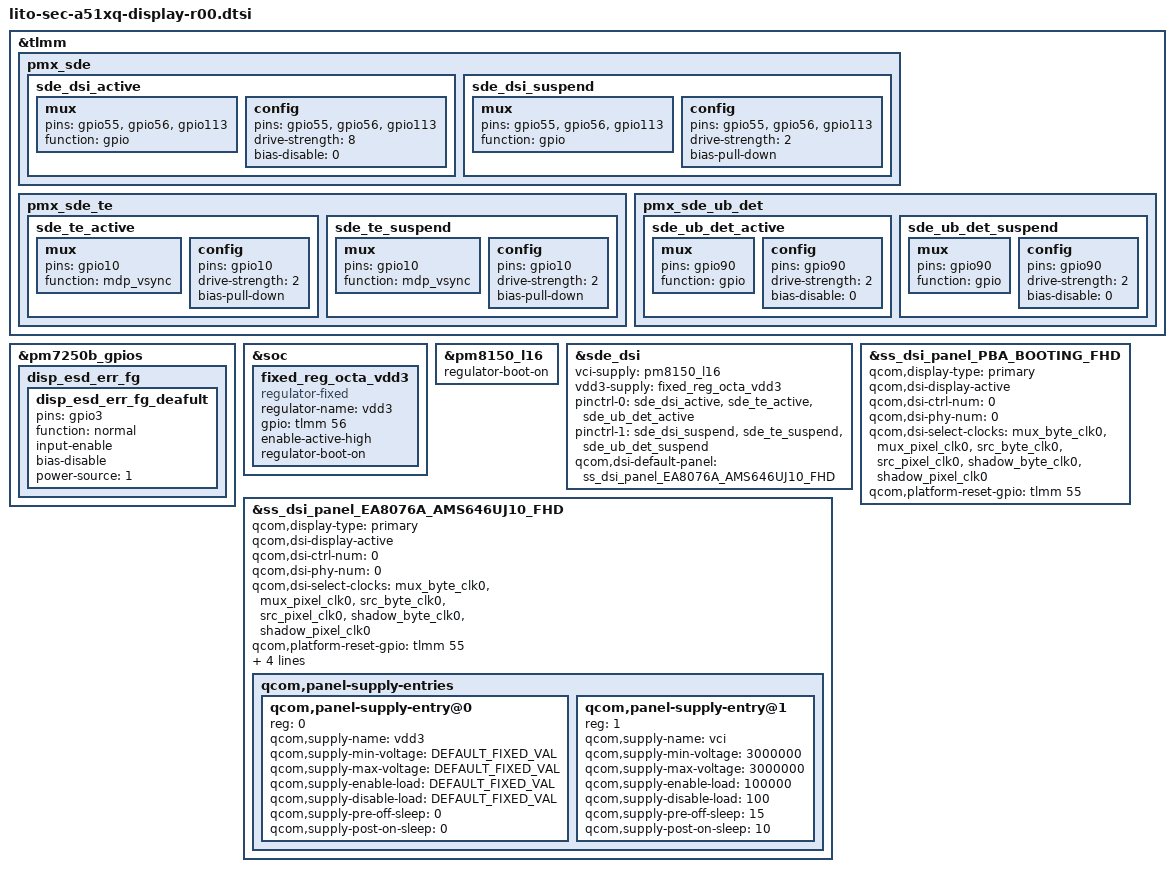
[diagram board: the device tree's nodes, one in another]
/* Copyright (c) 2016-2020, The Linux Foundation. All rights reserved.
 *
 * This program is free software; you can redistribute it and/or modify
 * it under the terms of the GNU General Public License version 2 and
 * only version 2 as published by the Free Software Foundation.
 *
 * This program is distributed in the hope that it will be useful,
 * but WITHOUT ANY WARRANTY; without even the implied warranty of
 * MERCHANTABILITY or FITNESS FOR A PARTICULAR PURPOSE.  See the
 * GNU General Public License for more details.
 */

#include "../../../../../../../techpack/display/msm/samsung/EA8076A_AMS646UJ10/dsi_panel_EA8076A_AMS646UJ10_fhd_octa_cmd.dtsi"
#include "../../../../../../../techpack/display/msm/samsung/PBA_BOOTING/dsi_panel_PBA_BOOTING_fhd_video.dtsi"

#define DEFAULT_FIXED_VAL	0

&tlmm {
	pmx_sde: pmx_sde {
		sde_dsi_active: sde_dsi_active {
			mux {
				pins = "gpio55", "gpio56", "gpio113";
				function = "gpio";
			};

			config {
				pins = "gpio55", "gpio56", "gpio113";
				drive-strength = <8>;   /* 8 mA */
				bias-disable = <0>;   /* no pull */
			};
		};
		sde_dsi_suspend: sde_dsi_suspend {
			mux {
				pins = "gpio55", "gpio56", "gpio113";
				function = "gpio";
			};

			config {
				pins = "gpio55", "gpio56", "gpio113";
				drive-strength = <2>;   /* 2 mA */
				bias-pull-down;         /* PULL DOWN */
			};
		};
	};

	pmx_sde_te {
		sde_te_active: sde_te_active {
			mux {
				pins = "gpio10";
				function = "mdp_vsync";
			};

			config {
				pins = "gpio10";
				drive-strength = <2>;   /* 2 mA */
				bias-pull-down;         /* PULL DOWN */
			};
		};

		sde_te_suspend: sde_te_suspend {
			mux {
				pins = "gpio10";
				function = "mdp_vsync";
			};

			config {
				pins = "gpio10";
				drive-strength = <2>;   /* 2 mA */
				bias-pull-down;         /* PULL DOWN */
			};
		};
	};

	pmx_sde_ub_det {
		sde_ub_det_active: sde_ub_det_active {	/* UB_CON_DET */
			mux {
				pins = "gpio90";
				function = "gpio";
			};

			config {
				pins = "gpio90";
				drive-strength = <2>;   /* 2 mA */
				bias-disable = <0>;   /* no pull */
			};
		};

		sde_ub_det_suspend: sde_ub_det_suspend {
			mux {
				pins = "gpio90";
				function = "gpio";
			};

			config {
				pins = "gpio90";
				drive-strength = <2>;   /* 2 mA */
				bias-disable = <0>;   /* no pull */
			};
		};
	};
};

&pm7250b_gpios {
	disp_esd_err_fg {
		disp_esd_err_fg_deafult: disp_esd_err_fg_deafult { // FG_ERR
			pins = "gpio3";
			function = "normal";
			input-enable;
			bias-disable;
			power-source = <1>;
		};
	};
};

&soc {
	fixed_reg_octa_vdd3: fixed_reg_octa_vdd3 {
		compatible = "regulator-fixed";
		status = "okay";
		regulator-name = "vdd3";
		gpio = <&tlmm 56 0>; /* 1.8V*/
		enable-active-high;
		regulator-boot-on;
	};
};

&pm8150_l16 {
	regulator-boot-on;
};

&sde_dsi {
	vci-supply = <&pm8150_l16>;
	vdd3-supply = <&fixed_reg_octa_vdd3>;

	pinctrl-names = "panel_active", "panel_suspend";
	pinctrl-0 = <&sde_dsi_active &sde_te_active &sde_ub_det_active>;
	pinctrl-1 = <&sde_dsi_suspend &sde_te_suspend &sde_ub_det_suspend>;

	qcom,dsi-default-panel =<&ss_dsi_panel_EA8076A_AMS646UJ10_FHD>;
};

&ss_dsi_panel_EA8076A_AMS646UJ10_FHD {
	qcom,display-type = "primary";
	qcom,dsi-display-active;

	qcom,dsi-ctrl-num = <0>;
	qcom,dsi-phy-num = <0>;
	qcom,dsi-select-clocks = "mux_byte_clk0", "mux_pixel_clk0",
				"src_byte_clk0", "src_pixel_clk0",
				"shadow_byte_clk0", "shadow_pixel_clk0";

	qcom,platform-reset-gpio = <&tlmm 55 0>;
	qcom,platform-te-gpio = <&tlmm 10 0>;

	samsung,ub-con-det = <&tlmm 90 0>; // UB_CON_DET
	samsung,support-optical-fingerprint;

	samsung,esd-irq-gpio1 = <&tlmm 113 0>; /* EL_ON1_DET */

	qcom,panel-supply-entries {
		#address-cells = <1>;
		#size-cells = <0>;

		/* use fixed regulator instead of samsung,panel-extra-power-gpio or qcom,platform-enable-gpio. */
		qcom,panel-supply-entry@0 {
			reg = <0>;
			qcom,supply-name = "vdd3"; // 1.8V
			qcom,supply-min-voltage = <DEFAULT_FIXED_VAL>;
			qcom,supply-max-voltage = <DEFAULT_FIXED_VAL>;
			qcom,supply-enable-load = <DEFAULT_FIXED_VAL>;
			qcom,supply-disable-load = <DEFAULT_FIXED_VAL>;
			qcom,supply-pre-off-sleep = <0>;
			qcom,supply-post-on-sleep = <0>;
		};

		qcom,panel-supply-entry@1 {
			reg = <1>;
			qcom,supply-name = "vci"; // 3.0 V
			qcom,supply-min-voltage = <3000000>;
			qcom,supply-max-voltage = <3000000>;
			qcom,supply-enable-load = <100000>;
			qcom,supply-disable-load = <100>;
			qcom,supply-pre-off-sleep = <15>;
			qcom,supply-post-on-sleep = <10>;
		};
	};
};

&ss_dsi_panel_PBA_BOOTING_FHD {
	qcom,display-type = "primary";
	qcom,dsi-display-active;

	qcom,dsi-ctrl-num = <0>;
	qcom,dsi-phy-num = <0>;
	qcom,dsi-select-clocks = "mux_byte_clk0", "mux_pixel_clk0",
				"src_byte_clk0", "src_pixel_clk0",
				"shadow_byte_clk0", "shadow_pixel_clk0";

	qcom,platform-reset-gpio = <&tlmm 55 0>;
};

